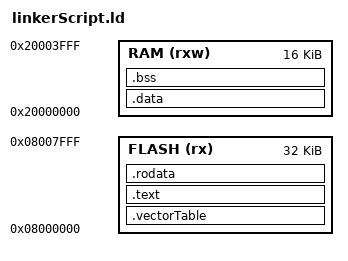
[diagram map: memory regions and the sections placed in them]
ENTRY(resetHandler)

_estack = 0x20004000;

MEMORY
{
    FLASH ( rx )      : ORIGIN = 0x08000000, LENGTH = 32K
    RAM ( rxw )       : ORIGIN = 0x20000000, LENGTH = 16K
}

SECTIONS
{
  .vectorTable :
  {
    . = ALIGN(4);
    KEEP (*(.vector_table))
    . = ALIGN(4);
  } >FLASH
  .text :
  {
    . = ALIGN(4);
    *(.text)
    *(.text*)
    . = ALIGN(4);
  } >FLASH
  .rodata :
  {
    . = ALIGN(4);
    *(.rodata)
    *(.rodata*)
    . = ALIGN(4);
  } >FLASH
  _sidata = .;
  .data : AT(_sidata)
  {
    . = ALIGN(4);
    /* Mark start/end locations for the 'data' section. */
    _sdata = .;
    *(.data)
    *(.data*)
    _edata = .;
    . = ALIGN(4);
  } >RAM
  .bss :
  {
    . = ALIGN(4);
    _sbss = .;
    *(.bss)
    *(.bss*)
    *(COMMON)
    . = ALIGN(4);
    _ebss = .;
  } >RAM
}
